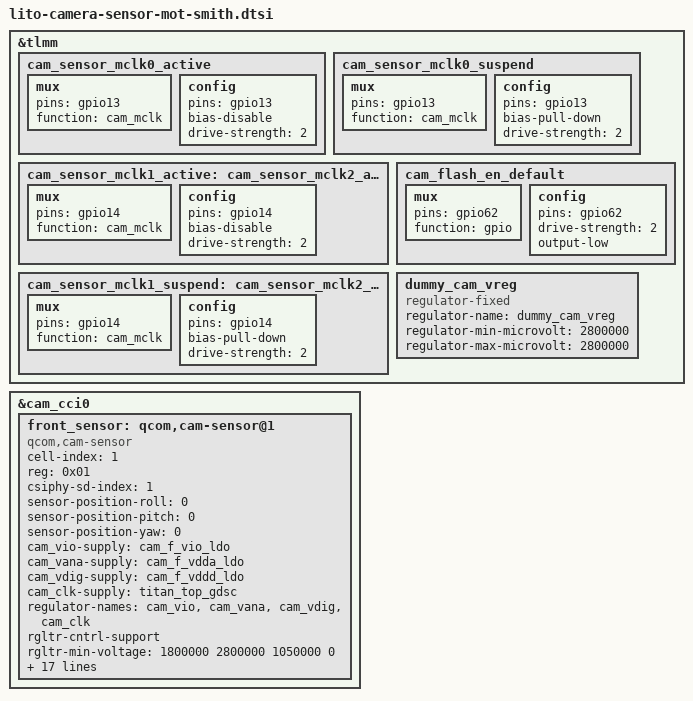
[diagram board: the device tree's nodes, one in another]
#include <dt-bindings/clock/qcom,camcc-lito.h>

&tlmm {
	cam_sensor_mclk0_active: cam_sensor_mclk0_active{
		/* MCLK0 */
		mux {
			pins = "gpio13";
			function = "cam_mclk";
		};

		config {
			pins = "gpio13";
			bias-disable; /* No PULL */
			drive-strength = <2>; /* 2 MA */
		};
	};

	cam_sensor_mclk0_suspend: cam_sensor_mclk0_suspend {
		/* MCLK0 */
		mux {
			pins = "gpio13";
			function = "cam_mclk";
		};

		config {
			pins = "gpio13";
			bias-pull-down; /* PULL DOWN */
			drive-strength = <2>; /* 2 MA */
		};
	};

	cam_sensor_mclk1_active: cam_sensor_mclk2_active {
		/* MCLK1 */
		mux {
			pins = "gpio14";
			function = "cam_mclk";
		};

		config {
			pins = "gpio14";
			bias-disable; /* No PULL */
			drive-strength = <2>; /* 2 MA */
		};
	};

	cam_sensor_mclk1_suspend: cam_sensor_mclk2_suspend {
		/* MCLK2 */
		mux {
			pins = "gpio14";
			function = "cam_mclk";
		};

		config {
			pins = "gpio14";
			bias-pull-down; /* PULL DOWN */
			drive-strength = <2>; /* 2 MA */
		};
	};

	cam_flash_en_default: cam_flash_en_default {
		/* RESET */
		mux {
			pins = "gpio62";
			function = "gpio";
		};

		config{
			pins = "gpio62";
			drive-strength = <2>; /* 2 MA */
			output-low;
		};
	};

	dummy_cam_vreg: dummy_cam_vreg {
		compatible = "regulator-fixed";
		status = "ok";
		regulator-name = "dummy_cam_vreg";
		regulator-min-microvolt = <2800000>;
		regulator-max-microvolt = <2800000>;
	};
};

&cam_cci0 {
	front_sensor: qcom,cam-sensor@1 {
		cell-index = <1>;
		compatible = "qcom,cam-sensor";
		reg = <0x01>;
		csiphy-sd-index = <1>; /* MIPI index of the CSIPHY bus, refere schematic for the location */
		sensor-position-roll = <0>;
		sensor-position-pitch = <0>;
		sensor-position-yaw = <0>;
		cam_vio-supply = <&cam_f_vio_ldo>;
		cam_vana-supply = <&cam_f_vdda_ldo>;
		cam_vdig-supply = <&cam_f_vddd_ldo>;
		cam_clk-supply = <&titan_top_gdsc>;
		regulator-names = "cam_vio", "cam_vana", "cam_vdig", "cam_clk";
		rgltr-cntrl-support;
		rgltr-min-voltage = <1800000 2800000 1050000 0>;
		rgltr-max-voltage = <1800000 2800000 1050000 0>;
		rgltr-load-current = < 1000 60000 200000 0>;
		gpio-no-mux = <0>;
		pinctrl-names = "cam_default", "cam_suspend";
		pinctrl-0 = <&cam_sensor_mclk0_active
					&cam_sensor_active_front>;
		pinctrl-1 = <&cam_sensor_mclk0_suspend
					&cam_sensor_suspend_front>;
		gpios = <&tlmm 13 0>,
			<&tlmm 32 0>;
		gpio-reset = <1>;
		gpio-req-tbl-num = <0 1>;
		gpio-req-tbl-flags = <1 0>;
		gpio-req-tbl-label = "CAMIF_MCLK0",
				"CAM_RESET0";
		sensor-mode = <0>;
		cci-master = <0>;
		status = "ok";
		clocks = <&camcc CAM_CC_MCLK0_CLK>;
		clock-names = "cam_clk";
		clock-cntl-level = "turbo";
		clock-rates = <24000000>;
	};
};

